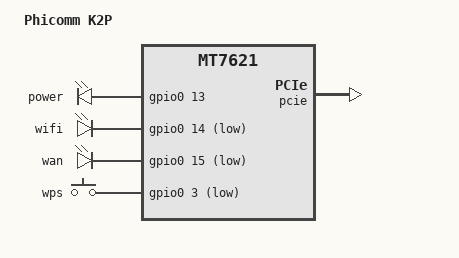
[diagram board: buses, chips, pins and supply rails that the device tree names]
/dts-v1/;

#include "mt7621.dtsi"
#include <dt-bindings/input/input.h>
#include "mt7621-spi-16m-layout.dtsi"
#include "mt7621-raeth-gmac2.dtsi"
#include "mt7621-pinctrl-default-gpio.dtsi"

/ {
	compatible = "mediatek,mt7621-soc";
	model = "Phicomm K2P";

	chosen {
		bootargs = "console=ttyS0,57600";
	};

	leds {
		compatible = "gpio-leds";

		// Power LED, active high on GPIO0_13
		stat_r {
			label = "power";
			gpios = <&gpio0 13 GPIO_ACTIVE_HIGH>;
		};

		// WiFi LED, active low on GPIO0_14
		stat_y {
			label = "wifi";
			gpios = <&gpio0 14 GPIO_ACTIVE_LOW>;
		};

		// WAN LED, active low on GPIO0_15
		stat_b {
			label = "wan";
			gpios = <&gpio0 15 GPIO_ACTIVE_LOW>;
		};
	};

	gpio-keys-polled {
		compatible = "gpio-keys-polled";
		poll-interval = <20>; // Poll every 20 ms

		// WPS button on GPIO0_3, active low
		wps {
			label = "wps";
			gpios = <&gpio0 3 GPIO_ACTIVE_LOW>;
			linux,code = <KEY_WPS_BUTTON>;
		};
	};
};

&pcie {
	status = "okay";
};
